# LKS32MC08x register map
Vendor: Linko Ltd.; Series: LKS32MC08x; File version: 1.0
CPU: CM0 r1p0, little endian, MPU, no FPU, 3 interrupt priority bits
Registers are 32-bit, read-write, reset 0x0 unless marked. A register's access mark holds for its fields unless they carry their own. Offsets are from the block's base; [hi:lo] are bit positions; {n}, {i} and the like mark numbered series.

## I2C — I2C registers
Base 0x40010400
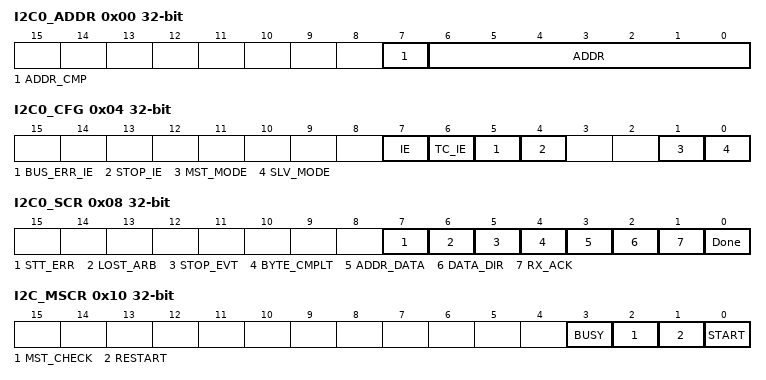
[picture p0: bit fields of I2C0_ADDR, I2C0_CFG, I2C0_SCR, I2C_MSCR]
0x00 I2C0_ADDR — I2C Device Address
  [7] ADDR_CMP — i2c address compared by hardware control bit
    0=Disabled (disable address compare by hardware); 1=Enabled (enable address compare by hardware)
  [6:0] ADDR — i2c device address
0x04 I2C0_CFG — I2C Configuration
  [7] IE — i2c interrupt enable
    0=Disabled (I2C interrupt is disabled); 1=Enabled (I2C interrupt is enabled)
  [6] TC_IE — i2c transfer complete interrupt enable
    0=Disabled (I2C transfer complete interrupt is disabled); 1=Enabled (I2C transfer complete interrupt is enabled)
  [5] BUS_ERR_IE — i2c bus error interrupt control bit
    0=Disabled (I2C bus error interrupt disable); 1=Enabled (I2C bus error interrupt enable.only valid in master mode, master will release bus to idle state)
  [4] STOP_IE — i2c bus error interrupt control bit
    0=Disabled (I2C stop interrupt is disabled); 1=Enabled (I2C stop interrupt is enabled)
  [1] MST_MODE — i2c master mode control bit
    0=Disabled (I2C master mode is disabled); 1=Enabled (I2C master mode is enabled)
  [0] SLV_MODE — i2c slave mode control bit
    0=Disabled (I2C slave mode is disabled); 1=Enabled (I2C slave mode is enabled)
0x08 I2C0_SCR — I2C State_Control
  [7] STT_ERR — i2c master mode, check out error start/stop.read out 1 means error start/stop happened, write 0 to clear
  [6] LOST_ARB ro — i2c master mode, lost control of bus.i2c master mode, lost control of bus,set this bit to 1.write 0 to clear
  [5] STOP_EVT — i2c stop event happened.read out 1 means stop event happened, write 0 to clear
  [4] BYTE_CMPLT — receive mode, receive done, send ack/nack.receive done, this bit is set to 1 to send ack;set to 0 to send nack.
  [3] ADDR_DATA — addr/data.receive is address data, set to 1; data set to 0. write 0 to clear
  [2] DATA_DIR — send/receive mode select
    0=Value (receive mode); 1=Value (send mode)
  [1] RX_ACK — send mode, sent done, receive ack/nack. send done. receive ack,this bit is set to 1; nack, this bit is set to 0.write 0 to clear
  [0] Done ro — transmit done.current transmit done, set this bit to 1.write 0 to clear
0x0C I2C0_DATA — I2C Data Regsiter
  [7:0] DATA — i2c data.send mode, write; receive mode, read
0x10 I2C_MSCR — I2C Master State_Control
  [3] BUSY ro — i2c busy/idle.bust start, set to 1; bus stop, set to 0
  [2] MST_CHECK ro — i2c device master mode feedback.i2c sends start, set this bit to 1, sends stop set this bit to 0.
  [1] RESTART — i2c generates restart signal.write 1 to generates restart signal, self clear.read out current state
  [0] START — i2c generates start signal.write 1 to generates start signal, self clear..read out current state
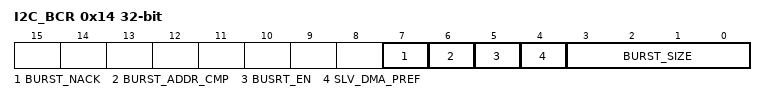
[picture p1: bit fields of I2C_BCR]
0x14 I2C_BCR — I2C Burst Control
  [7] BURST_NACK — send mode, handle nack
    0=Disabled (master is in send mode, return to stop. slave is in send mode, return to ilde); 1=Enabled (generates nack interrupt, pulldown i2c clock bus.)
  [6] BURST_ADDR_CMP — address cmp by hardware, generate interrupt or not
    0=Disabled (disable address compare by hardware in burst mode); 1=Enabled (enable address compare by hardware in burst mode)
  [5] BUSRT_EN — Burst Mode Control Bit
    0=Disabled (disable burst mode); 1=Enabled (enable burst mode)
  [4] SLV_DMA_PREF — Slave DMA prefetch enable
    0=Disabled (disable slave prefetch); 1=Enabled (enable slave prefetch)
  [3:0] BURST_SIZE

## CMP — CMP registers
Base 0x40010C00
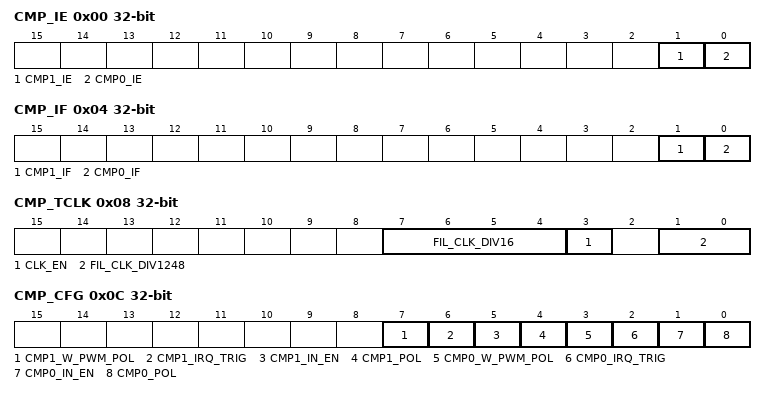
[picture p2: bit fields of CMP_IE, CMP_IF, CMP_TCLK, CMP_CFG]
0x00 CMP_IE — Comparator interrupt enable
  [1] CMP1_IE — Comparator 1 interrupt enable
    0=Disabled (irq disabled); 1=Enabled (irq enabled)
  [0] CMP0_IE — Comparator 0 interrupt enable
    0=Disabled (irq disabled); 1=Enabled (irq enabled)
0x04 CMP_IF — Comparator interrupt flag
  [1] CMP1_IF — Comparator 1 interrupt flag, write to clear
  [0] CMP0_IF — Comparator 0 interrupt flag, write to clear
0x08 CMP_TCLK — Comparator clock division control
  [7:4] FIL_CLK_DIV16 — Comparator filter clock divided by 1~16
  [3] CLK_EN — filter clock enable
  [1:0] FIL_CLK_DIV1248 — Comparator filter clock divided by 1/2/4/8
    0=1DIV (no division); 1=2DIV (1/2 division); 2=4DIV (1/4 division); 3=8DIV (1/8 division)
0x0C CMP_CFG — Comparator configuration
  [7] CMP1_W_PWM_POL — PWM signal polarity when used as Comparator 1 opening window contorl signal
  [6] CMP1_IRQ_TRIG — Comparator 1 irq trigger mechanism
    0=LEVEL_TRIG (Level trigger); 1=EDGE_TRIG (Edge trigger)
  [5] CMP1_IN_EN — Comparator 1 input enable
  [4] CMP1_POL — Comparator 1 polarity
    0=HIGH (high level effective); 1=LOW (low level effective)
  [3] CMP0_W_PWM_POL — PWM signal polarity when used as Comparator 0 opening window contorl signal
  [2] CMP0_IRQ_TRIG — Comparator 0 irq trigger mechanism
    0=LEVEL_TRIG (Level trigger); 1=EDGE_TRIG (Edge trigger)
  [1] CMP0_IN_EN — Comparator 0 input enable
  [0] CMP0_POL — Comparator 0 polarity
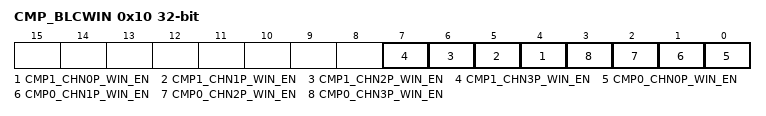
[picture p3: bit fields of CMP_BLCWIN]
0x10 CMP_BLCWIN — Comparator black window control
  [n+4] CMP1_CHN{n}P_WIN_EN (n=0..3) — Comparator 1 black window controled by CHN{n}P enable
  [n] CMP0_CHN{n}P_WIN_EN (n=0..3) — Comparator 0 black window controled by CHN{n}P enable
